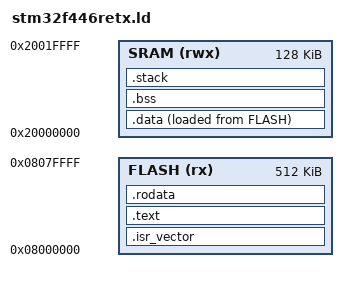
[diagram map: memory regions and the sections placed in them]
/* Linker script for STM32F446RE */

MEMORY
{
    FLASH (rx) : ORIGIN = 0x08000000, LENGTH = 512K
    SRAM (rwx) : ORIGIN = 0x20000000, LENGTH = 128K
}

SECTIONS
{
    .isr_vector :
    {
        KEEP(*(.isr_vector))
    } > FLASH

    .text :
    {
        *(.text*)
    } > FLASH

    .rodata :
    {
        *(.rodata*)
    } > FLASH

    .data :
    {
        _sdata = .;
        *(.data*)
        _edata = .;
    } > SRAM AT > FLASH

    .bss :
    {
        _sbss = .;
        *(.bss*)
        _ebss = .;
    } > SRAM

    .stack :
    {
        _sstack = .;
        . = . + 0x1000; /* 4 KiB stack */
        _estack = .;
    } > SRAM
}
